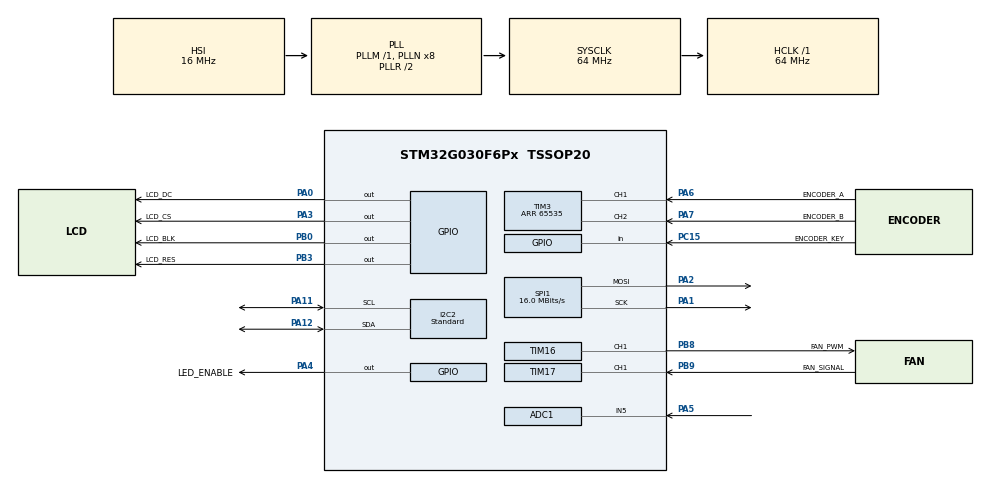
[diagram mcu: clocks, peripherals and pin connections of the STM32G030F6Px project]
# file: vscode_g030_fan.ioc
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ADC1.Channel-0\#ChannelRegularConversion=ADC_CHANNEL_5
ADC1.NbrOfConversionFlag=1
ADC1.Rank-0\#ChannelRegularConversion=1
ADC1.SamplingTime-0\#ChannelRegularConversion=ADC_SAMPLINGTIME_COMMON_1
ADC1.SamplingTimeCommon1=ADC_SAMPLETIME_160CYCLES_5
ADC1.SelectedChannel=ADC_CHANNEL_5
ADC1.master=1
I2C2.I2C_Speed_Mode=I2C_Standard
I2C2.Speed=100
I2C2.Timing=0x10B17DB5
Mcu.Family=STM32G0
Mcu.Name=STM32G030F6Px
Mcu.Package=TSSOP20
NVIC.TIM14_IRQn=true\:1\:0\:false\:false\:true\:true\:true\:true
NVIC.TIM17_IRQn=true\:0\:0\:false\:false\:true\:true\:true\:true
PA0.GPIO_Label=LCD_DC
PA0.GPIO_Speed=GPIO_SPEED_FREQ_VERY_HIGH
PA0.PinState=GPIO_PIN_SET
PA0.Signal=GPIO_Output
PA1.GPIO_Speed=GPIO_SPEED_FREQ_VERY_HIGH
PA1.Mode=TX_Only_Simplex_Unidirect_Master
PA1.Signal=SPI1_SCK
PA11\ [PA9].GPIO_Pu=GPIO_PULLUP
PA11\ [PA9].GPIO_Speed=GPIO_SPEED_FREQ_HIGH
PA11\ [PA9].Mode=I2C
PA11\ [PA9].PinState=GPIO_PIN_SET
PA11\ [PA9].Signal=I2C2_SCL
PA12\ [PA10].GPIO_Pu=GPIO_PULLUP
PA12\ [PA10].GPIO_Speed=GPIO_SPEED_FREQ_HIGH
PA12\ [PA10].Mode=I2C
PA12\ [PA10].PinState=GPIO_PIN_SET
PA12\ [PA10].Signal=I2C2_SDA
PA13.Mode=Serial_Wire
PA13.Signal=SYS_SWDIO
PA14-BOOT0.Mode=Serial_Wire
PA14-BOOT0.Signal=SYS_SWCLK
PA14-BOOT0__PA15.StandardMode=true
PA2.GPIO_Speed=GPIO_SPEED_FREQ_VERY_HIGH
PA2.Mode=TX_Only_Simplex_Unidirect_Master
PA2.Signal=SPI1_MOSI
PA3.GPIO_Label=LCD_CS
PA3.GPIO_Speed=GPIO_SPEED_FREQ_VERY_HIGH
PA3.PinState=GPIO_PIN_SET
PA3.Signal=GPIO_Output
PA4.GPIO_Label=LED_ENABLE
PA4.GPIO_Speed=GPIO_SPEED_FREQ_HIGH
PA4.PinState=GPIO_PIN_RESET
PA4.Signal=GPIO_Output
PA5.Mode=IN5
PA5.Signal=ADC1_IN5
PA6.GPIO_Label=ENCODER_A
PA6.GPIO_PuPd=GPIO_PULLUP
PA6.Signal=S_TIM3_CH1
PA7.GPIO_Label=ENCODER_B
PA7.GPIO_PuPd=GPIO_PULLUP
PA7.Signal=S_TIM3_CH2
PB0.GPIO_Label=LCD_BLK
PB0.PinState=GPIO_PIN_SET
PB0.Signal=GPIO_Output
PB0__PB1__PB2__PA8.StandardMode=true
PB3.GPIO_Label=LCD_RES
PB3.PinState=GPIO_PIN_SET
PB3.Signal=GPIO_Output
PB3__PB4__PB5__PB6.StandardMode=true
PB7__PB8.StandardMode=true
PB8.GPIO_FM8=__NULL
PB8.GPIO_Label=FAN_PWM
PB8.GPIO_Speed=GPIO_SPEED_FREQ_VERY_HIGH
PB8.Signal=S_TIM16_CH1
PB9.GPIO_Label=FAN_SIGNAL
PB9.GPIO_PuPd=GPIO_PULLUP
PB9.Signal=S_TIM17_CH1
PC14-OSC32_IN\ (PC14)__PB9.StandardMode=true
PC15-OSC32_OUT\ (PC15).GPIO_Label=ENCODER_KEY
PC15-OSC32_OUT\ (PC15).GPIO_PuPd=GPIO_PULLUP
PC15-OSC32_OUT\ (PC15).Signal=GPIO_Input
ProjectManager.HeapSize=0x200
ProjectManager.StackSize=0x400
ProjectManager.TargetToolchain=CMake
RCC.ADCFreq_Value=64000000
RCC.AHBFreq_Value=64000000
RCC.CortexFreq_Value=64000000
RCC.EXTERNAL_CLOCK_VALUE=12288000
RCC.HCLKFreq_Value=64000000
RCC.HSE_VALUE=8000000
RCC.HSI_VALUE=16000000
RCC.I2C1CLockSelection=RCC_I2C1CLKSOURCE_HSI
RCC.LSE_VALUE=32768
RCC.SYSCLKFreq_VALUE=64000000
RCC.SYSCLKSource=RCC_SYSCLKSOURCE_PLLCLK
RCC.VCOOutputFreq_Value=128000000
SH.S_TIM16_CH1.0=TIM16_CH1,PWM Generation1 CH1
SH.S_TIM17_CH1.0=TIM17_CH1,Input_Capture1_from_TI1
SH.S_TIM3_CH1.0=TIM3_CH1,Encoder_Interface
SH.S_TIM3_CH2.0=TIM3_CH2,Encoder_Interface
SPI1.BaudRatePrescaler=SPI_BAUDRATEPRESCALER_4
SPI1.CLKPhase=SPI_PHASE_1EDGE
SPI1.CLKPolarity=SPI_POLARITY_LOW
SPI1.CalculateBaudRate=16.0 MBits/s
SPI1.Direction=SPI_DIRECTION_2LINES
SPI1.Mode=SPI_MODE_MASTER
SPI1.VirtualType=VM_MASTER
TIM14.Period=9999
TIM14.Prescaler=63
TIM16.Channel=TIM_CHANNEL_1
TIM16.Period=2559
TIM16.Prescaler=0
TIM17.Channel=TIM_CHANNEL_1
TIM17.IC1Filter=15
TIM17.ICFilter_CH1=15
TIM17.Period=65535
TIM17.Prescaler=63
TIM3.EncoderMode=TIM_ENCODERMODE_TI12
TIM3.IC1Filter=15
TIM3.IC2Filter=15
TIM3.Period=65535
VP_TIM14_VS_ClockSourceINT.Mode=Enable_Timer
VP_TIM16_VS_ClockSourceINT.Mode=Enable_Timer
VP_TIM17_VS_ClockSourceINT.Mode=Enable_Timer
board=custom

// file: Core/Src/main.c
/* USER CODE BEGIN Header */
/**
  ******************************************************************************
  * @file           : main.c
  * @brief          : Main program body
  ******************************************************************************
  * @attention
  *
  * Copyright (c) 2026 STMicroelectronics.
  * All rights reserved.
  *
  * This software is licensed under terms that can be found in the LICENSE file
  * in the root directory of this software component.
  * If no LICENSE file comes with this software, it is provided AS-IS.
  *
  ******************************************************************************
  */
/* USER CODE END Header */
#include "main.h"
#include "adc.h"
#include "i2c.h"
#include "spi.h"
#include "tim.h"
#include "gpio.h"

/* USER CODE BEGIN Includes */
#include "control.h"
#include "show.h"
/* USER CODE END Includes */

void SystemClock_Config(void);

int main(void)
{

  /* MCU Configuration--------------------------------------------------------*/

  /* Reset of all peripherals, Initializes the Flash interface and the Systick. */
  HAL_Init();

  /* Configure the system clock */
  SystemClock_Config();

  /* Initialize all configured peripherals */
  MX_GPIO_Init();
  MX_SPI1_Init();
  MX_TIM3_Init();
  MX_TIM16_Init();
  MX_I2C2_Init();
  MX_TIM17_Init();
  MX_TIM14_Init();
  MX_ADC1_Init();
  /* USER CODE BEGIN 2 */
  /* 先完成 TFT 复位和延时，再允许风扇测速中断运行。 */
  Show_Init();

  /* 建立安全的 FAN/LED 输出状态，然后绘制完整的初始界面。 */
  Control_Init();
  Show_Update();

  /* TIM14 是应用层唯一的 10 ms 调度节拍源。 */
  LL_TIM_SetCounter(TIM14, 0U);
  LL_TIM_ClearFlag_UPDATE(TIM14);
  LL_TIM_EnableIT_UPDATE(TIM14);
  LL_TIM_EnableCounter(TIM14);
  /* USER CODE END 2 */

  /* Infinite loop */
  while (1)
  {

    /* USER CODE BEGIN 3 */
    /* 控制层返回状态变化时才刷新；动画随这些周期性状态更新同步推进。 */
    if (Control_Process())
    {
      Show_Update();
    }
  }
  /* USER CODE END 3 */
}

void SystemClock_Config(void)
{
  RCC_OscInitTypeDef RCC_OscInitStruct = {0};
  RCC_ClkInitTypeDef RCC_ClkInitStruct = {0};

  /** Configure the main internal regulator output voltage
  */
  HAL_PWREx_ControlVoltageScaling(PWR_REGULATOR_VOLTAGE_SCALE1);

  /** Initializes the RCC Oscillators according to the specified parameters
  * in the RCC_OscInitTypeDef structure.
  */
  RCC_OscInitStruct.OscillatorType = RCC_OSCILLATORTYPE_HSI;
  RCC_OscInitStruct.HSIState = RCC_HSI_ON;
  RCC_OscInitStruct.HSIDiv = RCC_HSI_DIV1;
  RCC_OscInitStruct.HSICalibrationValue = RCC_HSICALIBRATION_DEFAULT;
  RCC_OscInitStruct.PLL.PLLState = RCC_PLL_ON;
  RCC_OscInitStruct.PLL.PLLSource = RCC_PLLSOURCE_HSI;
  RCC_OscInitStruct.PLL.PLLM = RCC_PLLM_DIV1;
  RCC_OscInitStruct.PLL.PLLN = 8;
  RCC_OscInitStruct.PLL.PLLP = RCC_PLLP_DIV2;
  RCC_OscInitStruct.PLL.PLLR = RCC_PLLR_DIV2;
  if (HAL_RCC_OscConfig(&RCC_OscInitStruct) != HAL_OK)
  {
    Error_Handler();
  }

  /** Initializes the CPU, AHB and APB buses clocks
  */
  RCC_ClkInitStruct.ClockType = RCC_CLOCKTYPE_HCLK|RCC_CLOCKTYPE_SYSCLK
                              |RCC_CLOCKTYPE_PCLK1;
  RCC_ClkInitStruct.SYSCLKSource = RCC_SYSCLKSOURCE_PLLCLK;
  RCC_ClkInitStruct.AHBCLKDivider = RCC_SYSCLK_DIV1;
  RCC_ClkInitStruct.APB1CLKDivider = RCC_HCLK_DIV1;

  if (HAL_RCC_ClockConfig(&RCC_ClkInitStruct, FLASH_LATENCY_2) != HAL_OK)
  {
    Error_Handler();
  }
}

void Error_Handler(void)
{
  __disable_irq();
  while (1)
  {
  }
}
